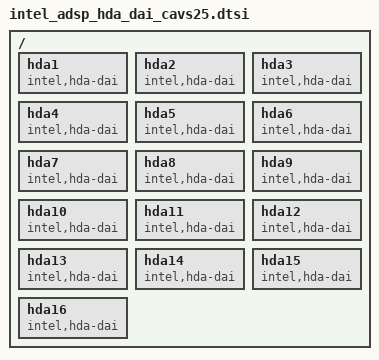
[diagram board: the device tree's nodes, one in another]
/*
 * Copyright (c) 2022 Intel Corporation
 *
 * SPDX-License-Identifier: Apache-2.0
 */

#include <xtensa/xtensa.dtsi>

/ {
	hda1: hda1 {
		compatible = "intel,hda-dai";
		status = "okay";
	};
	hda2: hda2 {
		compatible = "intel,hda-dai";
		status = "okay";
	};
	hda3: hda3 {
		compatible = "intel,hda-dai";
		status = "okay";
	};
	hda4: hda4 {
		compatible = "intel,hda-dai";
		status = "okay";
	};
	hda5: hda5 {
		compatible = "intel,hda-dai";
		status = "okay";
	};
	hda6: hda6 {
		compatible = "intel,hda-dai";
		status = "okay";
	};
	hda7: hda7 {
		compatible = "intel,hda-dai";
		status = "okay";
	};
	hda8: hda8 {
		compatible = "intel,hda-dai";
		status = "okay";
	};
	hda9: hda9 {
		compatible = "intel,hda-dai";
		status = "okay";
	};
	hda10: hda10 {
		compatible = "intel,hda-dai";
		status = "okay";
	};
	hda11: hda11 {
		compatible = "intel,hda-dai";
		status = "okay";
	};
	hda12: hda12 {
		compatible = "intel,hda-dai";
		status = "okay";
	};
	hda13: hda13 {
		compatible = "intel,hda-dai";
		status = "okay";
	};
	hda14: hda14 {
		compatible = "intel,hda-dai";
		status = "okay";
	};
	hda15: hda15 {
		compatible = "intel,hda-dai";
		status = "okay";
	};
	hda16: hda16 {
		compatible = "intel,hda-dai";
		status = "okay";
	};
};
